# f29h85x_error_aggregator_config_regs register map
Vendor: Texas Instruments
Peripheral module from a debugger description file (folder C29).
Registers are 32-bit, read-only, no defined reset value unless marked. A register's access mark holds for its fields unless they carry their own. Offsets are as the file gives them; lines under a group give offsets from that group; [hi:lo] are bit positions; {n}, {i} and the like mark numbered series; 'fields as' and 'values as' point back to an identical list; <NAME> marks a mode.

## ERROR_AGGREGATOR_CONFIG_REGS — ERROR AGGREGATOR CONFIG Registers
0x00 CPU1_PR_HIGHPRIO_ERROR_ADDRESS — CPU1 PR Error aggregator High Priority Error address register
  [31:0] CPU1_PR_HIGHPRIO_ERROR_ADDRESS — Address at which first High priority error occurred
0x04 CPU1_PR_LOWPRIO_ERROR_ADDRESS — CPU1 PR Error aggregator Low Priority Error address register
  [31:0] CPU1_PR_LOWPRIO_ERROR_ADDRESS — Address at which first Low priority error occurred
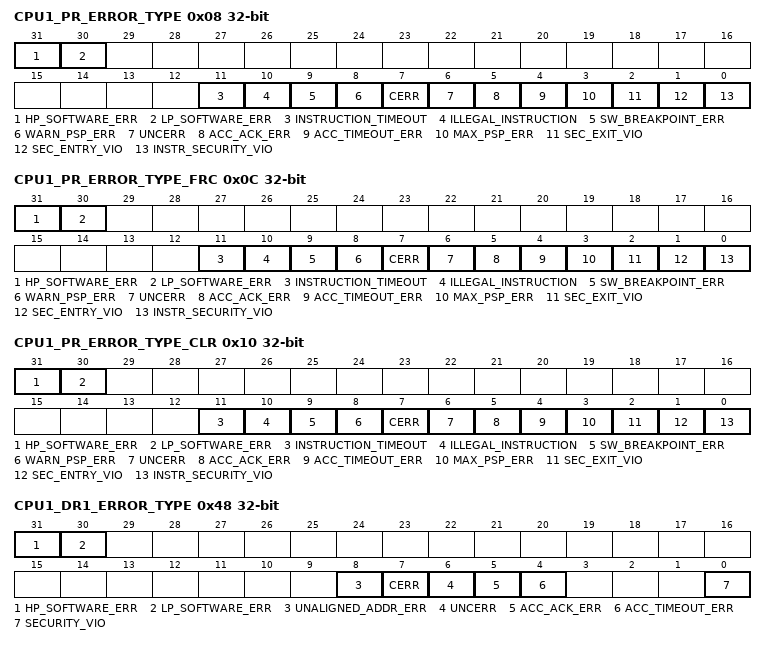
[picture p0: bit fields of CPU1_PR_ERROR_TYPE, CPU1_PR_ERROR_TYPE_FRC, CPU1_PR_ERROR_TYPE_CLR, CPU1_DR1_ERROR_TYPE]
0x08 CPU1_PR_ERROR_TYPE — CPU1 PR Error aggregator Error Type Register
  [31] HP_SOFTWARE_ERR — high priority error set by software
  [30] LP_SOFTWARE_ERR — Low Priority error set by software
  [11] INSTRUCTION_TIMEOUT — Instruction timeout error
  [10] ILLEGAL_INSTRUCTION — Illegal instruction error
  [9] SW_BREAKPOINT_ERR — Software brakepoint error
  [8] WARN_PSP_ERR — Warn PSP error
  [7] CERR — Correctable error
  [6] UNCERR — Uncorrectable error
  [5] ACC_ACK_ERR — Access ACK error
  [4] ACC_TIMEOUT_ERR — Access timeout error
  [3] MAX_PSP_ERR — MAX PSP error
  [2] SEC_EXIT_VIO — Secure exit error
  [1] SEC_ENTRY_VIO — Secure entry and linear code crossing error.
  [0] INSTR_SECURITY_VIO — Instruction packet security violation.
0x0C CPU1_PR_ERROR_TYPE_FRC rw — CPU1 PR Error aggregator Error Type Force Register
  [31] HP_SOFTWARE_ERR — Force high priority software error
  [30] LP_SOFTWARE_ERR — Force low priority software error
  [11] INSTRUCTION_TIMEOUT — Instruction timeout error force
  [10] ILLEGAL_INSTRUCTION — Illegal instruction error force
  [9] SW_BREAKPOINT_ERR — Software brakepoint error force
  [8] WARN_PSP_ERR — Warn PSP error force
  [7] CERR — Correctable error force
  [6] UNCERR — Uncorrectable error force
  [5] ACC_ACK_ERR — Access ACK error force
  [4] ACC_TIMEOUT_ERR — Access timeout error force
  [3] MAX_PSP_ERR — MAX PSP error force
  [2] SEC_EXIT_VIO — Secure exit error force
  [1] SEC_ENTRY_VIO — Secure entry and linear code crossing error force.
  [0] INSTR_SECURITY_VIO — Instruction packet security violation force.
0x10 CPU1_PR_ERROR_TYPE_CLR rw — CPU1 PR Error aggregator Error Type Clear Register
  [31] HP_SOFTWARE_ERR — clear high priority software error
  [30] LP_SOFTWARE_ERR — clear low priority software error
  [11] INSTRUCTION_TIMEOUT — Instruction timeout error clear
  [10] ILLEGAL_INSTRUCTION — Illegal instruction error clear
  [9] SW_BREAKPOINT_ERR — Software brakepoint error clear
  [8] WARN_PSP_ERR — Warn PSP error clear
  [7] CERR — Correctable error clear
  [6] UNCERR — Uncorrectable error clear
  [5] ACC_ACK_ERR — Access ACK error clear
  [4] ACC_TIMEOUT_ERR — Access timeout error clear
  [3] MAX_PSP_ERR — MAX PSP error clear
  [2] SEC_EXIT_VIO — Secure exit error clear
  [1] SEC_ENTRY_VIO — Secure entry and linear code crossing error clear.
  [0] INSTR_SECURITY_VIO — Instruction packet security violation clear.
0x14 CPU1_PR_PC — CPU1 PR Error aggregator Register to store PC value at the first High priority error event
  [31:0] CPU1_PR_PC — CPU1 PC at which first High priority error occurred
0x40 CPU1_DR1_HIGHPRIO_ERROR_ADDRESS — CPU1 DR1 Error aggregator High Priority Error address register
  [31:0] CPU1_DR1_HIGHPRIO_ERROR_ADDRESS — Address at which first High priority error occurred
0x44 CPU1_DR1_LOWPRIO_ERROR_ADDRESS — CPU1 DR1 Error aggregator Low Priority Error address register
  [31:0] CPU1_DR1_LOWPRIO_ERROR_ADDRESS — Address at which first Low priority error occurred
0x48 CPU1_DR1_ERROR_TYPE — CPU1 DR1 Error aggregator Error Type Register
  [31] HP_SOFTWARE_ERR — high priority error set by software
  [30] LP_SOFTWARE_ERR — Low Priority error set by software
  [8] UNALIGNED_ADDR_ERR — Unaligned address error
  [7] CERR — Correctable error
  [6] UNCERR — Uncorrectable error
  [5] ACC_ACK_ERR — Access ACK error
  [4] ACC_TIMEOUT_ERR — Access timeout error
  [0] SECURITY_VIO — Security violation
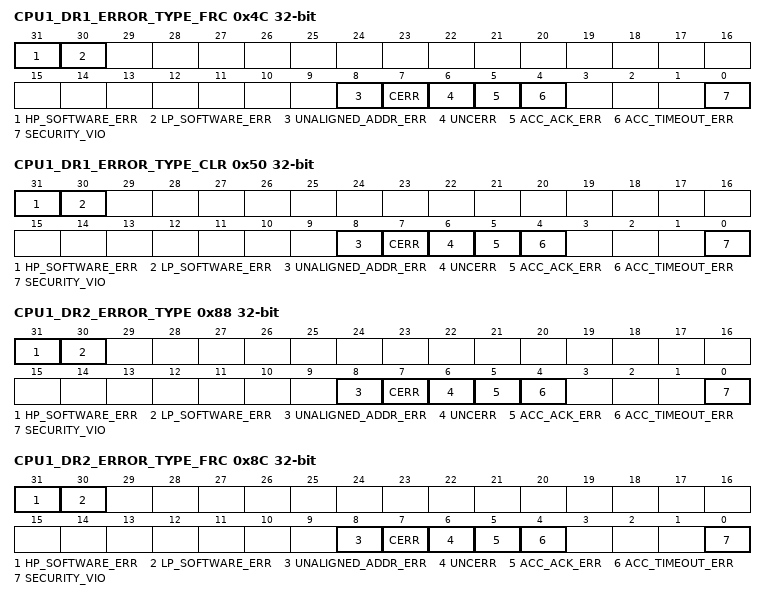
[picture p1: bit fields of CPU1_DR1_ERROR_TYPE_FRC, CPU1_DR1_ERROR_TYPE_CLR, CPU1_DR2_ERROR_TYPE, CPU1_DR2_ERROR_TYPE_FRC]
0x4C CPU1_DR1_ERROR_TYPE_FRC rw — CPU1 DR1 Error aggregator Error Type Force Register
  [31] HP_SOFTWARE_ERR — force high priority software error
  [30] LP_SOFTWARE_ERR — Force low priority software error
  [8] UNALIGNED_ADDR_ERR — Unaligned address error force
  [7] CERR — Correctable error force
  [6] UNCERR — Uncorrectable error force
  [5] ACC_ACK_ERR — Access ACK error force
  [4] ACC_TIMEOUT_ERR — Access timeout error force
  [0] SECURITY_VIO — Security violation force
0x50 CPU1_DR1_ERROR_TYPE_CLR rw — CPU1 DR1 Error aggregator Error Type Clear Register
  [31] HP_SOFTWARE_ERR — clear high priority software error
  [30] LP_SOFTWARE_ERR — clear low priority software error
  [8] UNALIGNED_ADDR_ERR — Unaligned address error clear
  [7] CERR — Correctable error clear
  [6] UNCERR — Uncorrectable error clear
  [5] ACC_ACK_ERR — Access ACK error clear
  [4] ACC_TIMEOUT_ERR — Access timeout error clear
  [0] SECURITY_VIO — Security violation clear
0x54 CPU1_DR1_PC — CPU1 DR1 Error aggregator Register to store PC value at the first High priority error event
  [31:0] CPU1_DR1_PC — CPU1 PC at which first High priority error occurred
0x80 CPU1_DR2_HIGHPRIO_ERROR_ADDRESS — CPU1 DR2 Error aggregator High Priority Error address register
  [31:0] CPU1_DR2_HIGHPRIO_ERROR_ADDRESS — Address at which first High priority error occurred
0x84 CPU1_DR2_LOWPRIO_ERROR_ADDRESS — CPU1 DR2 Error aggregator Low Priority Error address register
  [31:0] CPU1_DR2_LOWPRIO_ERROR_ADDRESS — Address at which first Low priority error occurred
0x88 CPU1_DR2_ERROR_TYPE — CPU1 DR2 Error aggregator Error Type Register
  fields as CPU1_DR1_ERROR_TYPE
0x8C CPU1_DR2_ERROR_TYPE_FRC rw — CPU1 DR2 Error aggregator Error Type Force Register
  fields as CPU1_DR1_ERROR_TYPE_FRC
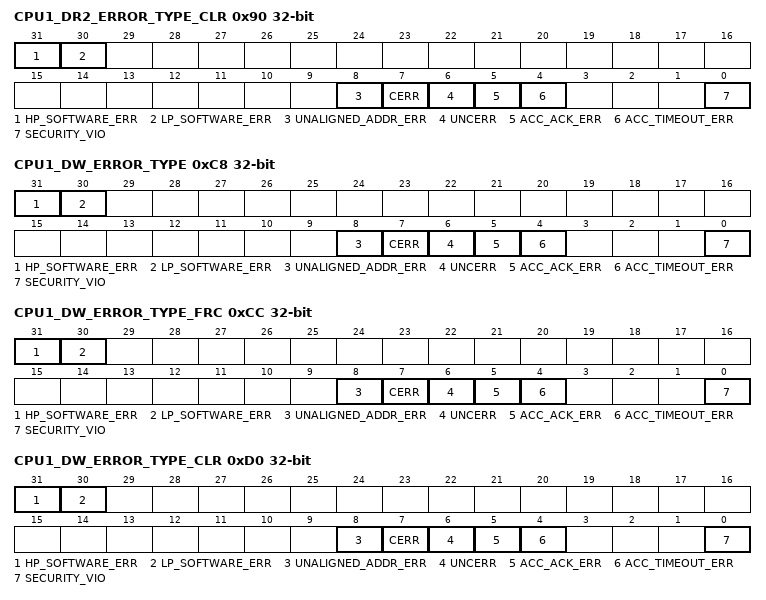
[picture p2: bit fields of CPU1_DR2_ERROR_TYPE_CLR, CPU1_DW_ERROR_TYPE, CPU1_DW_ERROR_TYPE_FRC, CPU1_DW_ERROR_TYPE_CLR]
0x90 CPU1_DR2_ERROR_TYPE_CLR rw — CPU1 DR2 Error aggregator Error Type Clear Register
  fields as CPU1_DR1_ERROR_TYPE_CLR
0x94 CPU1_DR2_PC — CPU1 DR2 Error aggregator Register to store PC value at the first High priority error event
  [31:0] CPU1_DR2_PC — CPU1 PC at which first High priority error occurred
0xC0 CPU1_DW_HIGHPRIO_ERROR_ADDRESS — CPU1 DW Error aggregator High Priority Error address register
  [31:0] CPU1_DW_HIGHPRIO_ERROR_ADDRESS — Address at which first High priority error occurred
0xC4 CPU1_DW_LOWPRIO_ERROR_ADDRESS — CPU1 DW Error aggregator Low Priority Error address register
  [31:0] CPU1_DW_LOWPRIO_ERROR_ADDRESS — Address at which first Low priority error occurred
0xC8 CPU1_DW_ERROR_TYPE — CPU1 DW Error aggregator Error Type Register
  fields as CPU1_DR1_ERROR_TYPE
0xCC CPU1_DW_ERROR_TYPE_FRC rw — CPU1 DW Error aggregator Error Type Force Register
  fields as CPU1_DR1_ERROR_TYPE_FRC
0xD0 CPU1_DW_ERROR_TYPE_CLR rw — CPU1 DW Error aggregator Error Type Clear Register
  fields as CPU1_DR1_ERROR_TYPE_CLR
0xD4 CPU1_DW_PC — CPU1 DW Error aggregator Register to store PC value at the first High priority error event
  [31:0] CPU1_DW_PC — CPU1 PC at which first High priority error occurred
0x100 CPU1_INT_HIGHPRIO_ERROR_ADDRESS — CPU1 INT Error aggregator High Priority Error address register
  [31:0] CPU1_INT_HIGHPRIO_ERROR_ADDRESS — Address at which first High priority error occurred
0x104 CPU1_INT_LOWPRIO_ERROR_ADDRESS — CPU1 INT Error aggregator Low Priority Error address register
  [31:0] CPU1_INT_LOWPRIO_ERROR_ADDRESS — Address at which first Low priority error occurred
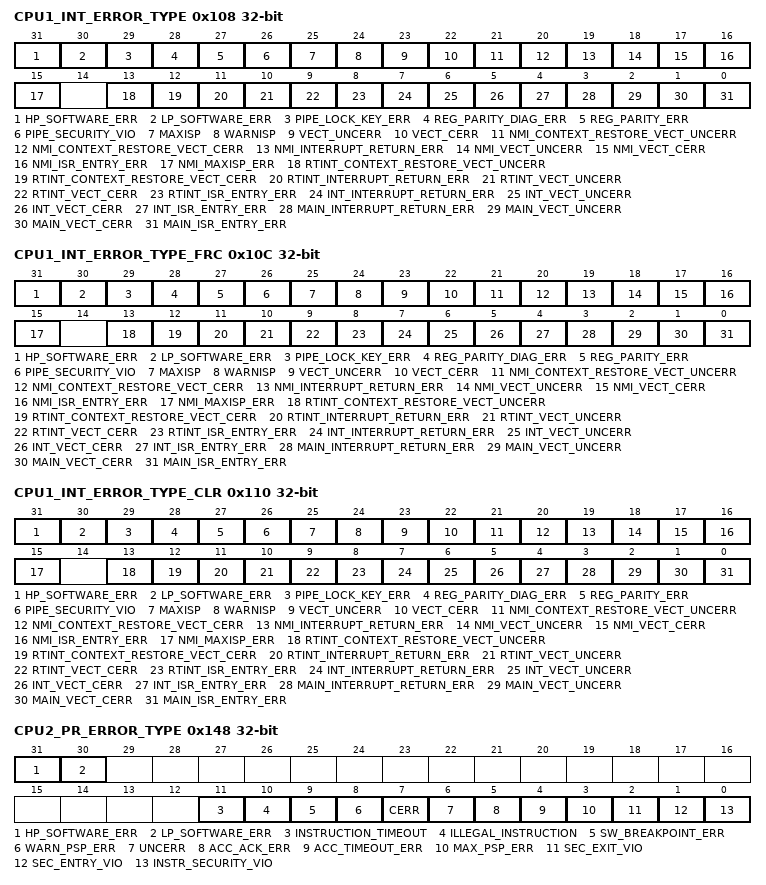
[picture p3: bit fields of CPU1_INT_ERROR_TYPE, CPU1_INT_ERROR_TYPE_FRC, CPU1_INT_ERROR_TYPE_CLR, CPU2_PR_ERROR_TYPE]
0x108 CPU1_INT_ERROR_TYPE — CPU1 INT Error aggregator Error Type Register
  [31] HP_SOFTWARE_ERR — high priority error set by software
  [30] LP_SOFTWARE_ERR — Low Priority error set by software
  [29] PIPE_LOCK_KEY_ERR — PIPE Lock/key error
  [28] REG_PARITY_DIAG_ERR — PIPE Register parity diag error
  [27] REG_PARITY_ERR — PIPE Reg parity error
  [26] PIPE_SECURITY_VIO — PIPE security violation
  [25] MAXISP
  [24] WARNISP
  [23] VECT_UNCERR — Vector Uncorrectable error
  [22] VECT_CERR — Vector Correctable error
  [21] NMI_CONTEXT_RESTORE_VECT_UNCERR — NMI Context restore Uncorrectable vector error
  [20] NMI_CONTEXT_RESTORE_VECT_CERR — NMI Context restore Correctable vector error
  [19] NMI_INTERRUPT_RETURN_ERR — NMI Interrupt return error
  [18] NMI_VECT_UNCERR — NMI Uncorrectable vector error
  [17] NMI_VECT_CERR — NMI Correctable vector error
  [16] NMI_ISR_ENTRY_ERR — NMI ISR entry error
  [15] NMI_MAXISP_ERR — NMI MAXISP error
  [13] RTINT_CONTEXT_RESTORE_VECT_UNCERR — RTINT Context restore Uncorrectable vector error
  [12] RTINT_CONTEXT_RESTORE_VECT_CERR — RTINT Context restore Correctable vector error
  [11] RTINT_INTERRUPT_RETURN_ERR — RTINT Interrupt return error
  [10] RTINT_VECT_UNCERR — RTINT Uncorrectable vector error
  [9] RTINT_VECT_CERR — RTINT Correctable vector error
  [8] RTINT_ISR_ENTRY_ERR — RTINT ISR entry error
  [7] INT_INTERRUPT_RETURN_ERR — INT INTerrupt return error
  [6] INT_VECT_UNCERR — INT Uncorrectable vector error
  [5] INT_VECT_CERR — INT Correctable vector error
  [4] INT_ISR_ENTRY_ERR — INT ISR entry error
  [3] MAIN_INTERRUPT_RETURN_ERR — Main Interrupt return error
  [2] MAIN_VECT_UNCERR — Main Uncorrectable vector error
  [1] MAIN_VECT_CERR — Main Correctable vector error
  [0] MAIN_ISR_ENTRY_ERR — Main ISR entry error
0x10C CPU1_INT_ERROR_TYPE_FRC rw — CPU1 INT Error aggregator Error Type Force Register
  [31] HP_SOFTWARE_ERR — force high priority software error
  [30] LP_SOFTWARE_ERR — Force low priority software error
  [29] PIPE_LOCK_KEY_ERR — PIPE Lock key error force
  [28] REG_PARITY_DIAG_ERR — PIPE Register parity diag error force
  [27] REG_PARITY_ERR — PIPE Reg parity error force
  [26] PIPE_SECURITY_VIO — PIPE security violation force
  [25] MAXISP — maxisp force
  [24] WARNISP — warnisp force
  [23] VECT_UNCERR — Vector Uncorrectable error force
  [22] VECT_CERR — Vector Correctable error force
  [21] NMI_CONTEXT_RESTORE_VECT_UNCERR — NMI Context restore Uncorrectable vector error force
  [20] NMI_CONTEXT_RESTORE_VECT_CERR — NMI Context restore Correctable vector error force
  [19] NMI_INTERRUPT_RETURN_ERR — NMI Interrupt return error force
  [18] NMI_VECT_UNCERR — NMI Uncorrectable vector error force
  [17] NMI_VECT_CERR — NMI Correctable vector error force
  [16] NMI_ISR_ENTRY_ERR — NMI ISR entry error force
  [15] NMI_MAXISP_ERR — NMI MAXISP error force
  [13] RTINT_CONTEXT_RESTORE_VECT_UNCERR — RTINT Context restore Uncorrectable vector error force
  [12] RTINT_CONTEXT_RESTORE_VECT_CERR — RTINT Context restore Correctable vector error force
  [11] RTINT_INTERRUPT_RETURN_ERR — RTINT Interrupt return error force
  [10] RTINT_VECT_UNCERR — RTINT Uncorrectable vector error force
  [9] RTINT_VECT_CERR — RTINT Correctable vector error force
  [8] RTINT_ISR_ENTRY_ERR — RTINT ISR entry error force
  [7] INT_INTERRUPT_RETURN_ERR — INT INTerrupt return error force
  [6] INT_VECT_UNCERR — INT Uncorrectable vector error force
  [5] INT_VECT_CERR — INT Correctable vector error force
  [4] INT_ISR_ENTRY_ERR — INT ISR entry error force
  [3] MAIN_INTERRUPT_RETURN_ERR — Main Interrupt return error force
  [2] MAIN_VECT_UNCERR — Main Uncorrectable vector error force
  [1] MAIN_VECT_CERR — Main Correctable vector error force
  [0] MAIN_ISR_ENTRY_ERR — Main ISR entry error force
0x110 CPU1_INT_ERROR_TYPE_CLR rw — CPU1 INT Error aggregator Error Type Clear Register
  [31] HP_SOFTWARE_ERR — clear high priority software error
  [30] LP_SOFTWARE_ERR — clear low priority software error
  [29] PIPE_LOCK_KEY_ERR — PIPE Lock key error clear
  [28] REG_PARITY_DIAG_ERR — PIPE Register parity diag error clear
  [27] REG_PARITY_ERR — PIPE Reg parity error clear
  [26] PIPE_SECURITY_VIO — PIPE security violation clear
  [25] MAXISP — maxisp clear
  [24] WARNISP — warnisp clear
  [23] VECT_UNCERR — Vector Uncorrectable error clear
  [22] VECT_CERR — Vector Correctable error clear
  [21] NMI_CONTEXT_RESTORE_VECT_UNCERR — NMI Context restore Uncorrectable vector error clear
  [20] NMI_CONTEXT_RESTORE_VECT_CERR — NMI Context restore Correctable vector error clear
  [19] NMI_INTERRUPT_RETURN_ERR — NMI Interrupt return error clear
  [18] NMI_VECT_UNCERR — NMI Uncorrectable vector error clear
  [17] NMI_VECT_CERR — NMI Correctable vector error clear
  [16] NMI_ISR_ENTRY_ERR — NMI ISR entry error clear
  [15] NMI_MAXISP_ERR — NMI MAXISP error clear
  [13] RTINT_CONTEXT_RESTORE_VECT_UNCERR — RTINT Context restore Uncorrectable vector error clear
  [12] RTINT_CONTEXT_RESTORE_VECT_CERR — RTINT Context restore Correctable vector error clear
  [11] RTINT_INTERRUPT_RETURN_ERR — RTINT Interrupt return error clear
  [10] RTINT_VECT_UNCERR — RTINT Uncorrectable vector error clear
  [9] RTINT_VECT_CERR — RTINT Correctable vector error clear
  [8] RTINT_ISR_ENTRY_ERR — RTINT ISR entry error clear
  [7] INT_INTERRUPT_RETURN_ERR — INT INTerrupt return error clear
  [6] INT_VECT_UNCERR — INT Uncorrectable vector error clear
  [5] INT_VECT_CERR — INT Correctable vector error clear
  [4] INT_ISR_ENTRY_ERR — INT ISR entry error clear
  [3] MAIN_INTERRUPT_RETURN_ERR — Main Interrupt return error clear
  [2] MAIN_VECT_UNCERR — Main Uncorrectable vector error clear
  [1] MAIN_VECT_CERR — Main Correctable vector error clear
  [0] MAIN_ISR_ENTRY_ERR — Main ISR entry error clear
0x114 CPU1_INT_PC — CPU1 INT Error aggregator Register to store PC value at the first High priority error event
  [31:0] CPU1_INT_PC — CPU1 PC at which first High priority error occurred
0x140 CPU2_PR_HIGHPRIO_ERROR_ADDRESS — CPU2 PR Error aggregator High Priority Error address register
  [31:0] CPU2_PR_HIGHPRIO_ERROR_ADDRESS — Address at which first High priority error occurred
0x144 CPU2_PR_LOWPRIO_ERROR_ADDRESS — CPU2 PR Error aggregator Low Priority Error address register
  [31:0] CPU2_PR_LOWPRIO_ERROR_ADDRESS — Address at which first Low priority error occurred
0x148 CPU2_PR_ERROR_TYPE — CPU2 PR Error aggregator Error Type Register
  fields as CPU1_PR_ERROR_TYPE
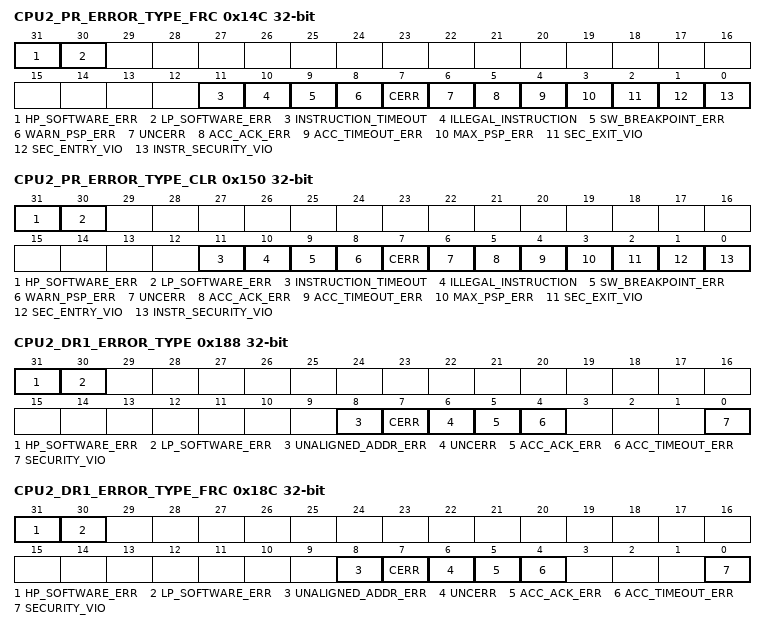
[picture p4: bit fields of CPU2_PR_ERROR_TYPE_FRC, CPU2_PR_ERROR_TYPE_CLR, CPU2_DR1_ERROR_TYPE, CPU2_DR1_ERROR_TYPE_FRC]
0x14C CPU2_PR_ERROR_TYPE_FRC rw — CPU2 PR Error aggregator Error Type Force Register
  fields as CPU1_PR_ERROR_TYPE_FRC
0x150 CPU2_PR_ERROR_TYPE_CLR rw — CPU2 PR Error aggregator Error Type Clear Register
  fields as CPU1_PR_ERROR_TYPE_CLR
0x154 CPU2_PR_PC — CPU2 PR Error aggregator Register to store PC value at the first High priority error event
  [31:0] CPU2_PR_PC — CPU2 PC at which first High priority error occurred
0x180 CPU2_DR1_HIGHPRIO_ERROR_ADDRESS — CPU2 DR1 Error aggregator High Priority Error address register
  [31:0] CPU2_DR1_HIGHPRIO_ERROR_ADDRESS — Address at which first High priority error occurred
0x184 CPU2_DR1_LOWPRIO_ERROR_ADDRESS — CPU2 DR1 Error aggregator Low Priority Error address register
  [31:0] CPU2_DR1_LOWPRIO_ERROR_ADDRESS — Address at which first Low priority error occurred
0x188 CPU2_DR1_ERROR_TYPE — CPU2 DR1 Error aggregator Error Type Register
  fields as CPU1_DR1_ERROR_TYPE
0x18C CPU2_DR1_ERROR_TYPE_FRC rw — CPU2 DR1 Error aggregator Error Type Force Register
  fields as CPU1_DR1_ERROR_TYPE_FRC
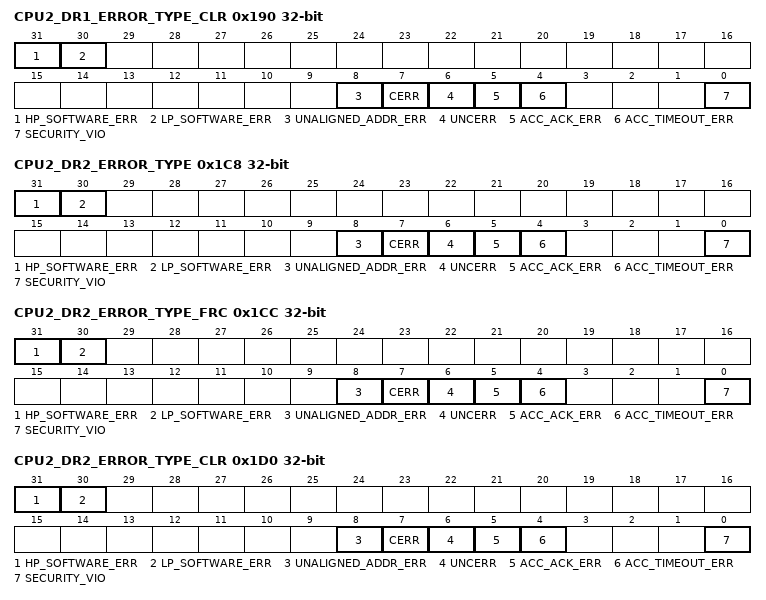
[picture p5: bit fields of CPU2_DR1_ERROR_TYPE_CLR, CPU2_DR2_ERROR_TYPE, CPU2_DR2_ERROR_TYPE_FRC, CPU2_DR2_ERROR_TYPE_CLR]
0x190 CPU2_DR1_ERROR_TYPE_CLR rw — CPU2 DR1 Error aggregator Error Type Clear Register
  fields as CPU1_DR1_ERROR_TYPE_CLR
0x194 CPU2_DR1_PC — CPU2 DR1 Error aggregator Register to store PC value at the first High priority error event
  [31:0] CPU2_DR1_PC — CPU2 PC at which first High priority error occurred
0x1C0 CPU2_DR2_HIGHPRIO_ERROR_ADDRESS — CPU2 DR2 Error aggregator High Priority Error address register
  [31:0] CPU2_DR2_HIGHPRIO_ERROR_ADDRESS — Address at which first High priority error occurred
0x1C4 CPU2_DR2_LOWPRIO_ERROR_ADDRESS — CPU2 DR2 Error aggregator Low Priority Error address register
  [31:0] CPU2_DR2_LOWPRIO_ERROR_ADDRESS — Address at which first Low priority error occurred
0x1C8 CPU2_DR2_ERROR_TYPE — CPU2 DR2 Error aggregator Error Type Register
  fields as CPU1_DR1_ERROR_TYPE
0x1CC CPU2_DR2_ERROR_TYPE_FRC rw — CPU2 DR2 Error aggregator Error Type Force Register
  fields as CPU1_DR1_ERROR_TYPE_FRC
0x1D0 CPU2_DR2_ERROR_TYPE_CLR rw — CPU2 DR2 Error aggregator Error Type Clear Register
  fields as CPU1_DR1_ERROR_TYPE_CLR
0x1D4 CPU2_DR2_PC — CPU2 DR2 Error aggregator Register to store PC value at the first High priority error event
  [31:0] CPU2_DR2_PC — CPU2 PC at which first High priority error occurred
0x200 CPU2_DW_HIGHPRIO_ERROR_ADDRESS — CPU2 DW Error aggregator High Priority Error address register
  [31:0] CPU2_DW_HIGHPRIO_ERROR_ADDRESS — Address at which first High priority error occurred
0x204 CPU2_DW_LOWPRIO_ERROR_ADDRESS — CPU2 DW Error aggregator Low Priority Error address register
  [31:0] CPU2_DW_LOWPRIO_ERROR_ADDRESS — Address at which first Low priority error occurred
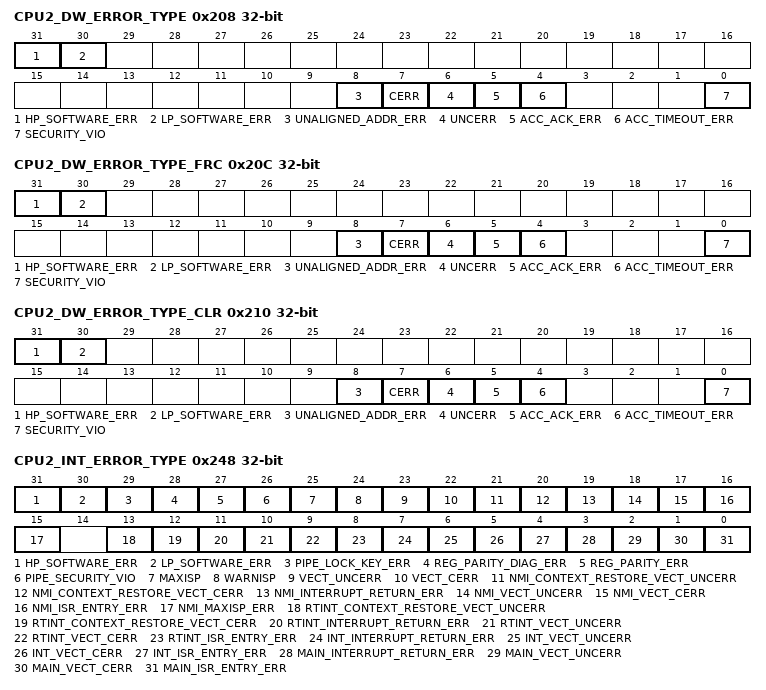
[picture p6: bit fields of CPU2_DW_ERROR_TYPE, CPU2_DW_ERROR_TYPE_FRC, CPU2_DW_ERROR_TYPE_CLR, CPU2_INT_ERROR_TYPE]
0x208 CPU2_DW_ERROR_TYPE — CPU2 DW Error aggregator Error Type Register
  fields as CPU1_DR1_ERROR_TYPE
0x20C CPU2_DW_ERROR_TYPE_FRC rw — CPU2 DW Error aggregator Error Type Force Register
  fields as CPU1_DR1_ERROR_TYPE_FRC
0x210 CPU2_DW_ERROR_TYPE_CLR rw — CPU2 DW Error aggregator Error Type Clear Register
  fields as CPU1_DR1_ERROR_TYPE_CLR
0x214 CPU2_DW_PC — CPU2 DW Error aggregator Register to store PC value at the first High priority error event
  [31:0] CPU2_DW_PC — CPU2 PC at which first High priority error occurred
0x240 CPU2_INT_HIGHPRIO_ERROR_ADDRESS — CPU2 INT Error aggregator High Priority Error address register
  [31:0] CPU2_INT_HIGHPRIO_ERROR_ADDRESS — Address at which first High priority error occurred
0x244 CPU2_INT_LOWPRIO_ERROR_ADDRESS — CPU2 INT Error aggregator Low Priority Error address register
  [31:0] CPU2_INT_LOWPRIO_ERROR_ADDRESS — Address at which first Low priority error occurred
0x248 CPU2_INT_ERROR_TYPE — CPU2 INT Error aggregator Error Type Register
  fields as CPU1_INT_ERROR_TYPE
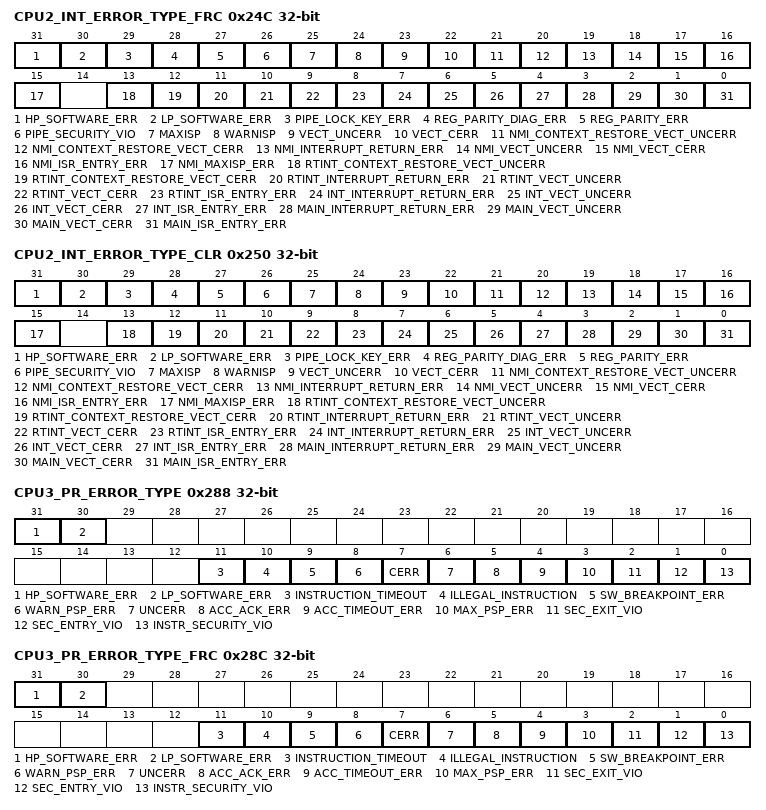
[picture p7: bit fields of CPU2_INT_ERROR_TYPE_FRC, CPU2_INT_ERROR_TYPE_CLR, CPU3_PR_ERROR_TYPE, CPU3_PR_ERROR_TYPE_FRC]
0x24C CPU2_INT_ERROR_TYPE_FRC rw — CPU2 INT Error aggregator Error Type Force Register
  fields as CPU1_INT_ERROR_TYPE_FRC
0x250 CPU2_INT_ERROR_TYPE_CLR rw — CPU2 INT Error aggregator Error Type Clear Register
  fields as CPU1_INT_ERROR_TYPE_CLR
0x254 CPU2_INT_PC — CPU2 INT Error aggregator Register to store PC value at the first High priority error event
  [31:0] CPU2_INT_PC — CPU2 PC at which first High priority error occurred
0x280 CPU3_PR_HIGHPRIO_ERROR_ADDRESS — CPU3 PR Error aggregator High Priority Error address register
  [31:0] CPU3_PR_HIGHPRIO_ERROR_ADDRESS — Address at which first High priority error occurred
0x284 CPU3_PR_LOWPRIO_ERROR_ADDRESS — CPU3 PR Error aggregator Low Priority Error address register
  [31:0] CPU3_PR_LOWPRIO_ERROR_ADDRESS — Address at which first Low priority error occurred
0x288 CPU3_PR_ERROR_TYPE — CPU3 PR Error aggregator Error Type Register
  fields as CPU1_PR_ERROR_TYPE
0x28C CPU3_PR_ERROR_TYPE_FRC rw — CPU3 PR Error aggregator Error Type Force Register
  fields as CPU1_PR_ERROR_TYPE_FRC
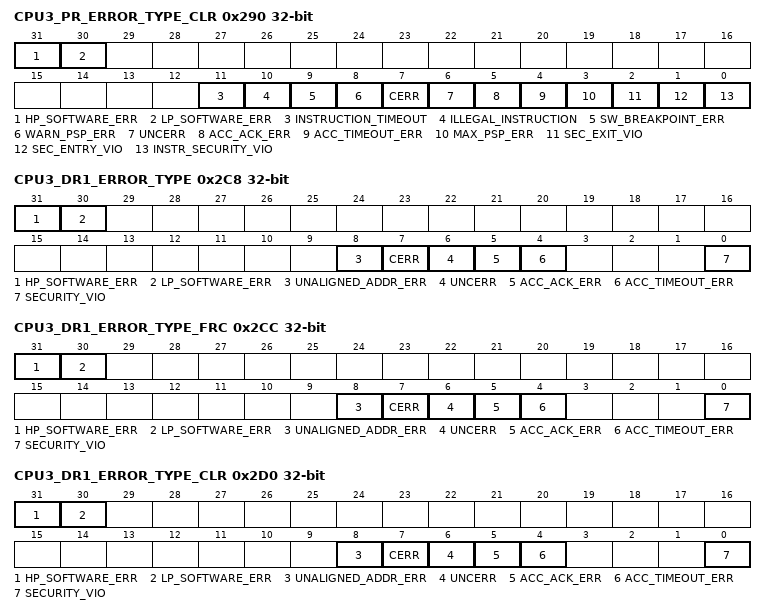
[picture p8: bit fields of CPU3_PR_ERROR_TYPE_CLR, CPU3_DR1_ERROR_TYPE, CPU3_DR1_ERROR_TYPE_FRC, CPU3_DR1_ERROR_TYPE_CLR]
0x290 CPU3_PR_ERROR_TYPE_CLR rw — CPU3 PR Error aggregator Error Type Clear Register
  fields as CPU1_PR_ERROR_TYPE_CLR
0x294 CPU3_PR_PC — CPU3 PR Error aggregator Register to store PC value at the first High priority error event
  [31:0] CPU3_PR_PC — CPU3 PC at which first High priority error occurred
0x2C0 CPU3_DR1_HIGHPRIO_ERROR_ADDRESS — CPU3 DR1 Error aggregator High Priority Error address register
  [31:0] CPU3_DR1_HIGHPRIO_ERROR_ADDRESS — Address at which first High priority error occurred
0x2C4 CPU3_DR1_LOWPRIO_ERROR_ADDRESS — CPU3 DR1 Error aggregator Low Priority Error address register
  [31:0] CPU3_DR1_LOWPRIO_ERROR_ADDRESS — Address at which first Low priority error occurred
0x2C8 CPU3_DR1_ERROR_TYPE — CPU3 DR1 Error aggregator Error Type Register
  fields as CPU1_DR1_ERROR_TYPE
0x2CC CPU3_DR1_ERROR_TYPE_FRC rw — CPU3 DR1 Error aggregator Error Type Force Register
  fields as CPU1_DR1_ERROR_TYPE_FRC
0x2D0 CPU3_DR1_ERROR_TYPE_CLR rw — CPU3 DR1 Error aggregator Error Type Clear Register
  fields as CPU1_DR1_ERROR_TYPE_CLR
0x2D4 CPU3_DR1_PC — CPU3 DR1 Error aggregator Register to store PC value at the first High priority error event
  [31:0] CPU3_DR1_PC — CPU3 PC at which first High priority error occurred
0x300 CPU3_DR2_HIGHPRIO_ERROR_ADDRESS — CPU3 DR2 Error aggregator High Priority Error address register
  [31:0] CPU3_DR2_HIGHPRIO_ERROR_ADDRESS — Address at which first High priority error occurred
0x304 CPU3_DR2_LOWPRIO_ERROR_ADDRESS — CPU3 DR2 Error aggregator Low Priority Error address register
  [31:0] CPU3_DR2_LOWPRIO_ERROR_ADDRESS — Address at which first Low priority error occurred
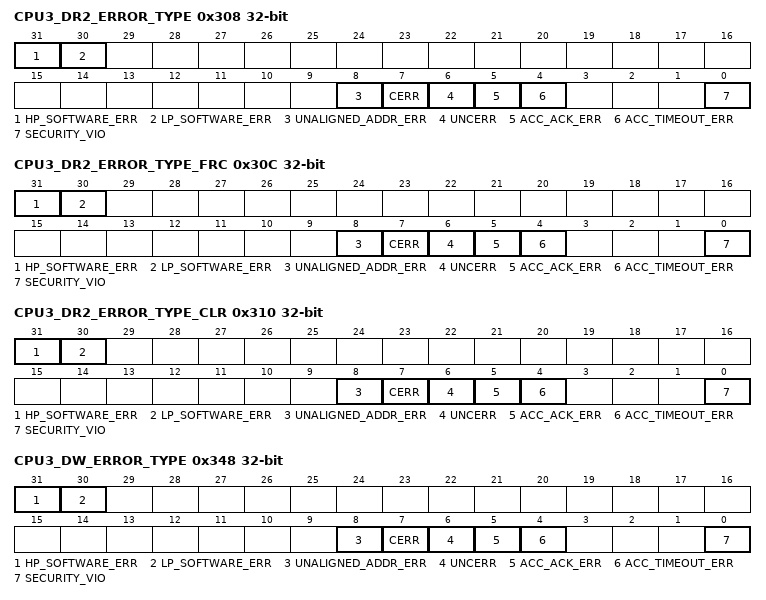
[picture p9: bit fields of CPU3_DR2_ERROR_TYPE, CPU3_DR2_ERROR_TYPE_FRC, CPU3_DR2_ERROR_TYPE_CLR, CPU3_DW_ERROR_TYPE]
0x308 CPU3_DR2_ERROR_TYPE — CPU3 DR2 Error aggregator Error Type Register
  fields as CPU1_DR1_ERROR_TYPE
0x30C CPU3_DR2_ERROR_TYPE_FRC rw — CPU3 DR2 Error aggregator Error Type Force Register
  fields as CPU1_DR1_ERROR_TYPE_FRC
0x310 CPU3_DR2_ERROR_TYPE_CLR rw — CPU3 DR2 Error aggregator Error Type Clear Register
  fields as CPU1_DR1_ERROR_TYPE_CLR
0x314 CPU3_DR2_PC — CPU3 DR2 Error aggregator Register to store PC value at the first High priority error event
  [31:0] CPU3_DR2_PC — CPU3 PC at which first High priority error occurred
0x340 CPU3_DW_HIGHPRIO_ERROR_ADDRESS — CPU3 DW Error aggregator High Priority Error address register
  [31:0] CPU3_DW_HIGHPRIO_ERROR_ADDRESS — Address at which first High priority error occurred
0x344 CPU3_DW_LOWPRIO_ERROR_ADDRESS — CPU3 DW Error aggregator Low Priority Error address register
  [31:0] CPU3_DW_LOWPRIO_ERROR_ADDRESS — Address at which first Low priority error occurred
0x348 CPU3_DW_ERROR_TYPE — CPU3 DW Error aggregator Error Type Register
  fields as CPU1_DR1_ERROR_TYPE
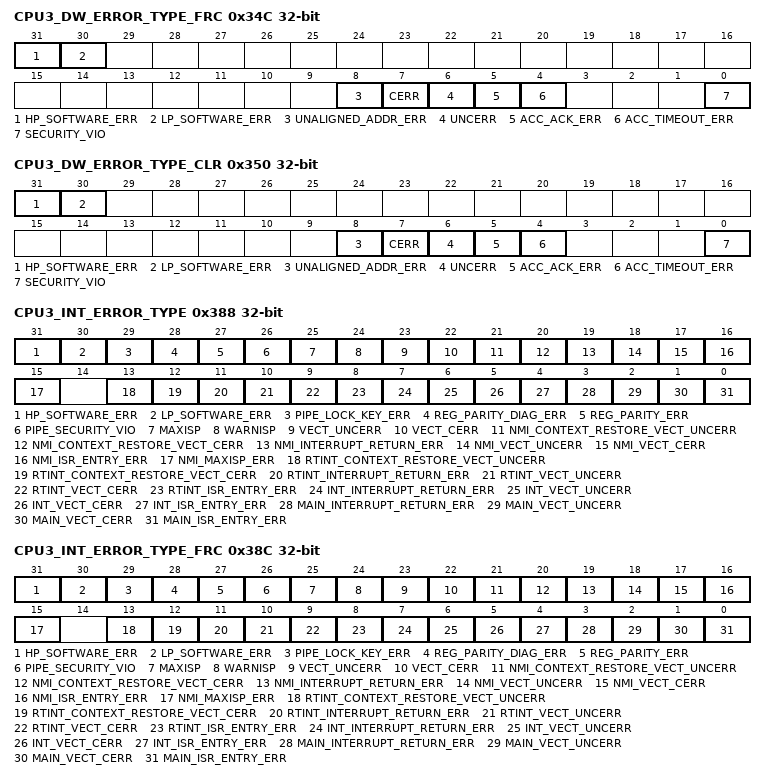
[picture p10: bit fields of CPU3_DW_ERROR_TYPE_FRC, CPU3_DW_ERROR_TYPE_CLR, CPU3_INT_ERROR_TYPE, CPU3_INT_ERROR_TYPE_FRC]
0x34C CPU3_DW_ERROR_TYPE_FRC rw — CPU3 DW Error aggregator Error Type Force Register
  fields as CPU1_DR1_ERROR_TYPE_FRC
0x350 CPU3_DW_ERROR_TYPE_CLR rw — CPU3 DW Error aggregator Error Type Clear Register
  fields as CPU1_DR1_ERROR_TYPE_CLR
0x354 CPU3_DW_PC — CPU3 DW Error aggregator Register to store PC value at the first High priority error event
  [31:0] CPU3_DW_PC — CPU3 PC at which first High priority error occurred
0x380 CPU3_INT_HIGHPRIO_ERROR_ADDRESS — CPU3 INT Error aggregator High Priority Error address register
  [31:0] CPU3_INT_HIGHPRIO_ERROR_ADDRESS — Address at which first High priority error occurred
0x384 CPU3_INT_LOWPRIO_ERROR_ADDRESS — CPU3 INT Error aggregator Low Priority Error address register
  [31:0] CPU3_INT_LOWPRIO_ERROR_ADDRESS — Address at which first Low priority error occurred
0x388 CPU3_INT_ERROR_TYPE — CPU3 INT Error aggregator Error Type Register
  fields as CPU1_INT_ERROR_TYPE
0x38C CPU3_INT_ERROR_TYPE_FRC rw — CPU3 INT Error aggregator Error Type Force Register
  fields as CPU1_INT_ERROR_TYPE_FRC
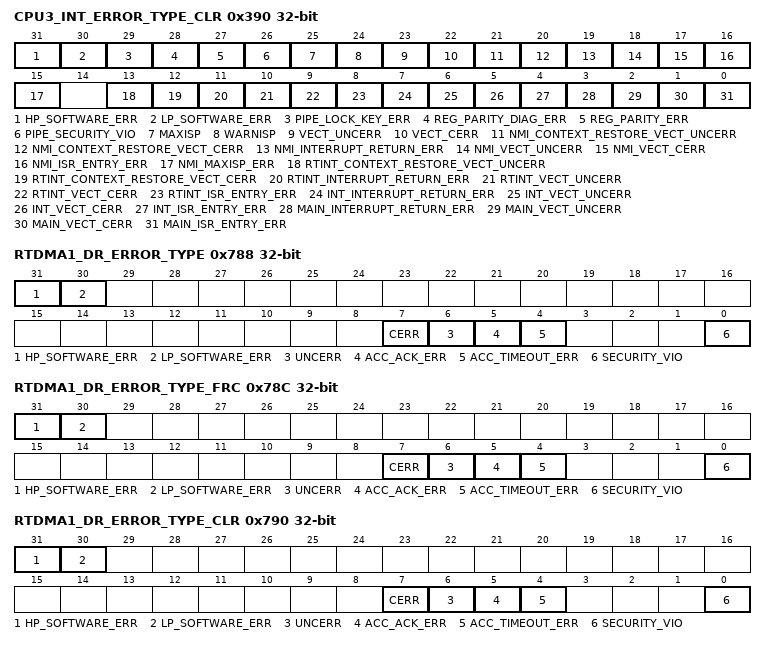
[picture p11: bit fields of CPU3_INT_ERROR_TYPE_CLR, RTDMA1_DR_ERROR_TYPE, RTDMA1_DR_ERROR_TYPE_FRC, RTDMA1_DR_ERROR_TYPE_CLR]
0x390 CPU3_INT_ERROR_TYPE_CLR rw — CPU3 INT Error aggregator Error Type Clear Register
  fields as CPU1_INT_ERROR_TYPE_CLR
0x394 CPU3_INT_PC — CPU3 INT Error aggregator Register to store PC value at the first High priority error event
  [31:0] CPU3_INT_PC — CPU3 PC at which first High priority error occurred
0x780 RTDMA1_DR_HIGHPRIO_ERROR_ADDRESS — RTDMA1 DR Error aggregator High Priority Error address register
  [31:0] RTDMA1_DR_HIGHPRIO_ERROR_ADDRESS — Address at which first High priority error occurred
0x784 RTDMA1_DR_LOWPRIO_ERROR_ADDRESS — RTDMA1 DR Error aggregator Low Priority Error address register
  [31:0] RTDMA1_DR_LOWPRIO_ERROR_ADDRESS — Address at which first Low priority error occurred
0x788 RTDMA1_DR_ERROR_TYPE — RTDMA1 DR Error aggregator Error Type Register
  [31] HP_SOFTWARE_ERR — high priority error set by software
  [30] LP_SOFTWARE_ERR — Low priority software error
  [7] CERR — Correctable error
  [6] UNCERR — Uncorrectable error
  [5] ACC_ACK_ERR — Access ACK error
  [4] ACC_TIMEOUT_ERR — Access timeout error
  [0] SECURITY_VIO — Security violation
0x78C RTDMA1_DR_ERROR_TYPE_FRC rw — RTDMA1 DR Error aggregator Error Type Force Register
  [31] HP_SOFTWARE_ERR — force high priority software error
  [30] LP_SOFTWARE_ERR — Force low priority software error
  [7] CERR — Correctable error force
  [6] UNCERR — Uncorrectable error force
  [5] ACC_ACK_ERR — Access ACK error force
  [4] ACC_TIMEOUT_ERR — Access timeout error force
  [0] SECURITY_VIO — Security violation force
0x790 RTDMA1_DR_ERROR_TYPE_CLR rw — RTDMA1 DR Error aggregator Error Type Clear Register
  [31] HP_SOFTWARE_ERR — clear high priority software error
  [30] LP_SOFTWARE_ERR — clear low priority software error
  [7] CERR — Correctable error clear
  [6] UNCERR — Uncorrectable error clear
  [5] ACC_ACK_ERR — Access ACK error clear
  [4] ACC_TIMEOUT_ERR — Access timeout error clear
  [0] SECURITY_VIO — Security violation clear
0x7C0 RTDMA1_DW_HIGHPRIO_ERROR_ADDRESS — RTDMA1 DW Error aggregator High Priority Error address register
  [31:0] RTDMA1_DW_HIGHPRIO_ERROR_ADDRESS — Address at which first High priority error occurred
0x7C4 RTDMA1_DW_LOWPRIO_ERROR_ADDRESS — RTDMA1 DW Error aggregator Low Priority Error address register
  [31:0] RTDMA1_DW_LOWPRIO_ERROR_ADDRESS — Address at which first Low priority error occurred
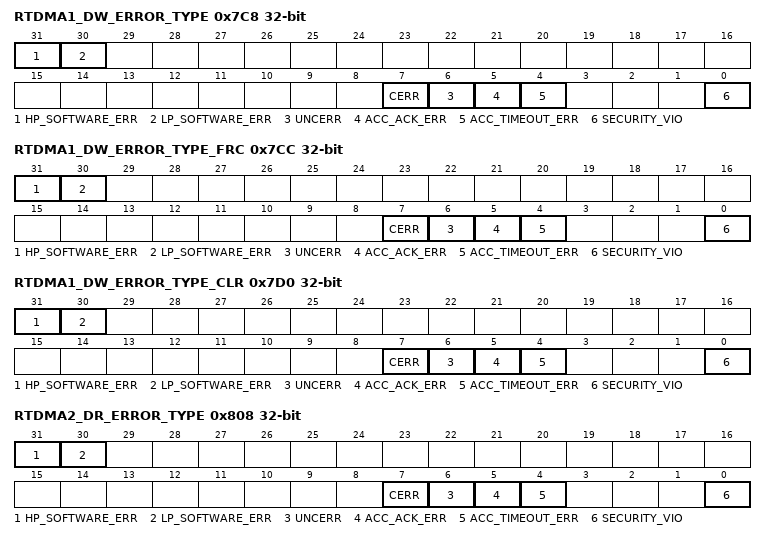
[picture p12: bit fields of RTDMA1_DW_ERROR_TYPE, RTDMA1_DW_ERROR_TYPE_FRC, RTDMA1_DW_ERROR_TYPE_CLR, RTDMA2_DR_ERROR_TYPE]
0x7C8 RTDMA1_DW_ERROR_TYPE — RTDMA1 DW Error aggregator Error Type Register
  [31] HP_SOFTWARE_ERR — high priority error set by software
  [30] LP_SOFTWARE_ERR — Low Priority error set by software
  [7] CERR — Correctable error
  [6] UNCERR — Uncorrectable error
  [5] ACC_ACK_ERR — Access ACK error
  [4] ACC_TIMEOUT_ERR — Access timeout error
  [0] SECURITY_VIO — Security violation
0x7CC RTDMA1_DW_ERROR_TYPE_FRC rw — RTDMA1 DW Error aggregator Error Type Force Register
  fields as RTDMA1_DR_ERROR_TYPE_FRC
0x7D0 RTDMA1_DW_ERROR_TYPE_CLR rw — RTDMA1 DW Error aggregator Error Type Clear Register
  fields as RTDMA1_DR_ERROR_TYPE_CLR
0x800 RTDMA2_DR_HIGHPRIO_ERROR_ADDRESS — RTDMA2 DR Error aggregator High Priority Error address register
  [31:0] RTDMA2_DR_HIGHPRIO_ERROR_ADDRESS — Address at which first High priority error occurred
0x804 RTDMA2_DR_LOWPRIO_ERROR_ADDRESS — RTDMA2 DR Error aggregator Low Priority Error address register
  [31:0] RTDMA2_DR_LOWPRIO_ERROR_ADDRESS — Address at which first Low priority error occurred
0x808 RTDMA2_DR_ERROR_TYPE — RTDMA2 DR Error aggregator Error Type Register
  fields as RTDMA1_DR_ERROR_TYPE
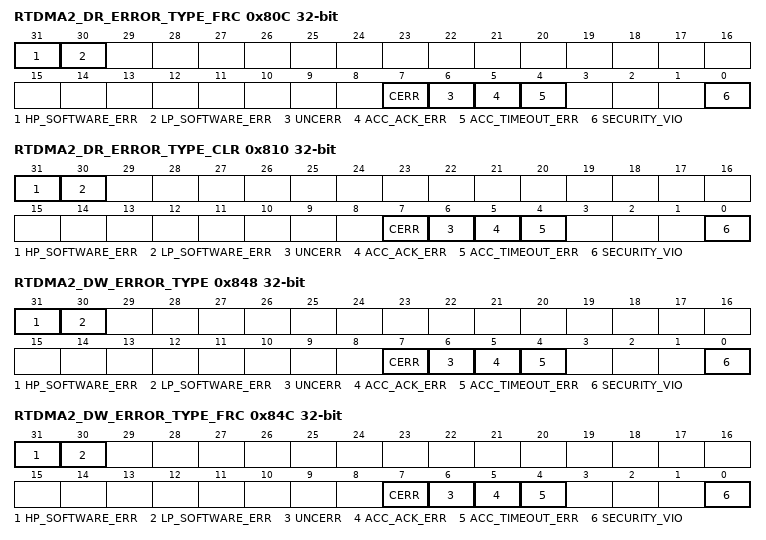
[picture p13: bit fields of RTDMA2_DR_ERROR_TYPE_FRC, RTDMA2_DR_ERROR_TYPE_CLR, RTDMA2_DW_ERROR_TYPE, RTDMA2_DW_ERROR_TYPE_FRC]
0x80C RTDMA2_DR_ERROR_TYPE_FRC rw — RTDMA2 DR Error aggregator Error Type Force Register
  fields as RTDMA1_DR_ERROR_TYPE_FRC
0x810 RTDMA2_DR_ERROR_TYPE_CLR rw — RTDMA2 DR Error aggregator Error Type Clear Register
  fields as RTDMA1_DR_ERROR_TYPE_CLR
0x840 RTDMA2_DW_HIGHPRIO_ERROR_ADDRESS — RTDMA2 DW Error aggregator High Priority Error address register
  [31:0] RTDMA2_DW_HIGHPRIO_ERROR_ADDRESS — Address at which first High priority error occurred
0x844 RTDMA2_DW_LOWPRIO_ERROR_ADDRESS — RTDMA2 DW Error aggregator Low Priority Error address register
  [31:0] RTDMA2_DW_LOWPRIO_ERROR_ADDRESS — Address at which first Low priority error occurred
0x848 RTDMA2_DW_ERROR_TYPE — RTDMA2 DW Error aggregator Error Type Register
  fields as RTDMA1_DW_ERROR_TYPE
0x84C RTDMA2_DW_ERROR_TYPE_FRC rw — RTDMA2 DW Error aggregator Error Type Force Register
  fields as RTDMA1_DR_ERROR_TYPE_FRC
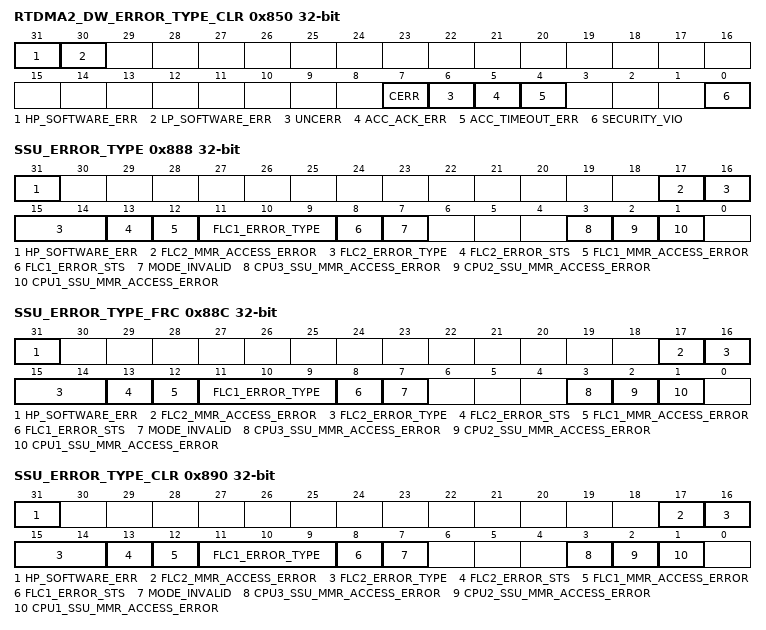
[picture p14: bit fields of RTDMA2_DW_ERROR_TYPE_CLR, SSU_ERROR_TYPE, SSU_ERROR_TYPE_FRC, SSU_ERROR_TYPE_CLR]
0x850 RTDMA2_DW_ERROR_TYPE_CLR rw — RTDMA2 DW Error aggregator Error Type Clear Register
  fields as RTDMA1_DR_ERROR_TYPE_CLR
0x880 SSU_HIGHPRIO_ERROR_ADDRESS — SSU Error aggregator High Priority Error address register
  [31:0] SSU_HIGHPRIO_ERROR_ADDRESS — Address at which first high priority SSU error occurred
0x888 SSU_ERROR_TYPE — SSU Error aggregator Error Type Register
  [31] HP_SOFTWARE_ERR — high priority error set by software
  [17] FLC2_MMR_ACCESS_ERROR
  [16:14] FLC2_ERROR_TYPE
  [13] FLC2_ERROR_STS
  [12] FLC1_MMR_ACCESS_ERROR
  [11:9] FLC1_ERROR_TYPE
  [8] FLC1_ERROR_STS
  [7] MODE_INVALID — BANKMAP, SECVALID, BANKMODE, SSUMODE invalid
  [3] CPU3_SSU_MMR_ACCESS_ERROR
  [2] CPU2_SSU_MMR_ACCESS_ERROR
  [1] CPU1_SSU_MMR_ACCESS_ERROR
0x88C SSU_ERROR_TYPE_FRC rw — SSU Error aggregator Error Type Force Register
  [31] HP_SOFTWARE_ERR — force high priority software error
  [17] FLC2_MMR_ACCESS_ERROR — FLC2_MMR_ACCESS_ERROR force
  [16:14] FLC2_ERROR_TYPE — FLC2_ERROR_TYPE force
  [13] FLC2_ERROR_STS — FLC2_ ERROR_STS force
  [12] FLC1_MMR_ACCESS_ERROR — FLC1_MMR_ACCESS_ERROR force
  [11:9] FLC1_ERROR_TYPE — FLC1_ERROR_TYPE force
  [8] FLC1_ERROR_STS — FLC1_ERROR_STS force
  [7] MODE_INVALID — BANKMAP, SECVALID, BANKMODE, SSUMODE invalid force
  [3] CPU3_SSU_MMR_ACCESS_ERROR — CPU3_SSU_MMR_ACCESS_ERROR force
  [2] CPU2_SSU_MMR_ACCESS_ERROR — CPU2_SSU_MMR_ACCESS_ERROR force
  [1] CPU1_SSU_MMR_ACCESS_ERROR — CPU1_SSU_MMR_ACCESS_ERROR force
0x890 SSU_ERROR_TYPE_CLR rw — SSU Error aggregator Error Type Clear Register
  [31] HP_SOFTWARE_ERR — clear high priority software error
  [17] FLC2_MMR_ACCESS_ERROR — FLC2_MMR_ACCESS_ERROR Clear
  [16:14] FLC2_ERROR_TYPE — FLC2_ERROR_TYPE Clear
  [13] FLC2_ERROR_STS — FLC2_ ERROR_STS Clear
  [12] FLC1_MMR_ACCESS_ERROR — FLC1_MMR_ACCESS_ERROR Clear
  [11:9] FLC1_ERROR_TYPE — FLC1_ERROR_TYPE Clear
  [8] FLC1_ERROR_STS — FLC1_ERROR_STS Clear
  [7] MODE_INVALID — BANKMAP, SECVALID, BANKMODE, SSUMODE invalid Clear
  [3] CPU3_SSU_MMR_ACCESS_ERROR — CPU3_SSU_MMR_ACCESS_ERROR Clear
  [2] CPU2_SSU_MMR_ACCESS_ERROR — CPU2_SSU_MMR_ACCESS_ERROR Clear
  [1] CPU1_SSU_MMR_ACCESS_ERROR — CPU1_SSU_MMR_ACCESS_ERROR Clear
0x8C0 ETHERCAT_HIGHPRIO_ERROR_ADDRESS — ETHERCAT Error aggregator High Priority Error address register
  [31:0] ETHERCAT_HIGHPRIO_ERROR_ADDRESS — Address at which first High priority error occurred
0x8C8 ETHERCAT_ERROR_TYPE — ETHERCAT Error aggregator Error Type Register
  [31] HP_SOFTWARE_ERR — high priority error set by software
  [6] UNCERR — Uncorrectable error
0x8CC ETHERCAT_ERROR_TYPE_FRC rw — ETHERCAT Error aggregator Error Type Force Register
  [31] HP_SOFTWARE_ERR — force high priority software error
  [6] UNCERR — Uncorrectable error force
0x8D0 ETHERCAT_ERROR_TYPE_CLR rw — ETHERCAT Error aggregator Error Type Clear Register
  [31] HP_SOFTWARE_ERR — clear high priority software error
  [6] UNCERR — Uncorrectable error clear
